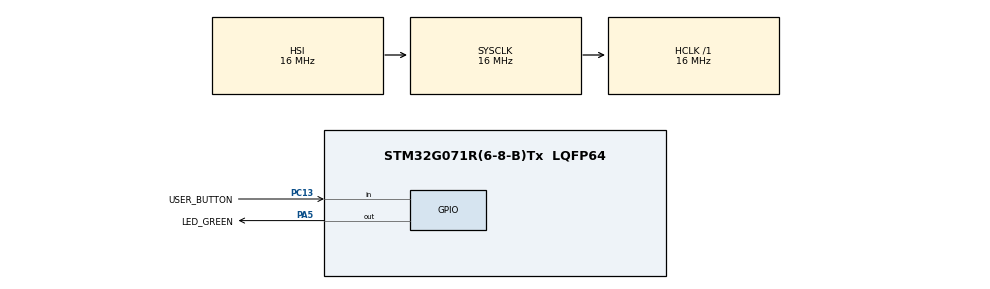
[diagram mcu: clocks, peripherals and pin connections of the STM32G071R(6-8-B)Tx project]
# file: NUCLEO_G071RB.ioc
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Mcu.Family=STM32G0
Mcu.Name=STM32G071R(6-8-B)Tx
Mcu.Package=LQFP64
PA13.GPIO_Label=TMS
PA13.Mode=Serial_Wire
PA13.Signal=SYS_SWDIO
PA14-BOOT0.GPIO_Label=TCK
PA14-BOOT0.Mode=Serial_Wire
PA14-BOOT0.Signal=SYS_SWCLK
PA5.GPIO_Label=LED_GREEN
PA5.GPIO_Speed=GPIO_SPEED_FREQ_HIGH
PA5.Signal=GPIO_Output
PC13.GPIO_Label=USER_BUTTON
PC13.GPIO_PuPd=GPIO_NOPULL
PC13.Signal=GPIO_Input
PC14-OSC32_IN\ (PC14).Mode=LSE-External-Oscillator
PC14-OSC32_IN\ (PC14).Signal=RCC_OSC32_IN
PC15-OSC32_OUT\ (PC15).Mode=LSE-External-Oscillator
PC15-OSC32_OUT\ (PC15).Signal=RCC_OSC32_OUT
PF0-OSC_IN\ (PF0).GPIO_Label=MCO
PF0-OSC_IN\ (PF0).Mode=HSE-External-Clock-Source
PF0-OSC_IN\ (PF0).Signal=RCC_OSC_IN
ProjectManager.HeapSize=0x200
ProjectManager.StackSize=0x400
ProjectManager.TargetToolchain=CMake
RCC.AHBFreq_Value=16000000
RCC.CortexFreq_Value=16000000
RCC.EXTERNAL_CLOCK_VALUE=12288000
RCC.HCLKFreq_Value=16000000
RCC.HSE_VALUE=8000000
RCC.HSI_VALUE=16000000
RCC.SYSCLKFreq_VALUE=16000000
RCC.VCOOutputFreq_Value=128000000
board=NUCLEO-G071RB

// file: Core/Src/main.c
/* USER CODE BEGIN Header */
/**
  ******************************************************************************
  * @file           : main.c
  * @brief          : Main program body
  ******************************************************************************
  * @attention
  *
  * Copyright (c) 2025 STMicroelectronics.
  * All rights reserved.
  *
  * This software is licensed under terms that can be found in the LICENSE file
  * in the root directory of this software component.
  * If no LICENSE file comes with this software, it is provided AS-IS.
  *
  ******************************************************************************
  */
/* USER CODE END Header */
#include "main.h"

/* USER CODE BEGIN Includes */
#include "main_app.h"
/* USER CODE END Includes */

void SystemClock_Config(void);
static void MX_GPIO_Init(void);

int main(void)
{

  /* MCU Configuration--------------------------------------------------------*/

  /* Reset of all peripherals, Initializes the Flash interface and the Systick. */
  HAL_Init();

  /* USER CODE BEGIN Init */
  // TESTS
  /* USER CODE END Init */

  /* Configure the system clock */
  SystemClock_Config();

  /* Initialize all configured peripherals */
  MX_GPIO_Init();

  /* Infinite loop */
  /* USER CODE BEGIN WHILE */
  while (1)
  {
    main_app();
    // if(GPIO_PIN_RESET == HAL_GPIO_ReadPin(USER_BUTTON_GPIO_Port, USER_BUTTON_Pin))
    // {
    //   HAL_GPIO_TogglePin( LED_GREEN_GPIO_Port, LED_GREEN_Pin);
    //   HAL_Delay(500);
    // }
    /* USER CODE END WHILE */

  }
}

void SystemClock_Config(void)
{
  RCC_OscInitTypeDef RCC_OscInitStruct = {0};
  RCC_ClkInitTypeDef RCC_ClkInitStruct = {0};

  /** Configure the main internal regulator output voltage
  */
  HAL_PWREx_ControlVoltageScaling(PWR_REGULATOR_VOLTAGE_SCALE1);

  /** Initializes the RCC Oscillators according to the specified parameters
  * in the RCC_OscInitTypeDef structure.
  */
  RCC_OscInitStruct.OscillatorType = RCC_OSCILLATORTYPE_HSI;
  RCC_OscInitStruct.HSIState = RCC_HSI_ON;
  RCC_OscInitStruct.HSIDiv = RCC_HSI_DIV1;
  RCC_OscInitStruct.HSICalibrationValue = RCC_HSICALIBRATION_DEFAULT;
  RCC_OscInitStruct.PLL.PLLState = RCC_PLL_NONE;
  if (HAL_RCC_OscConfig(&RCC_OscInitStruct) != HAL_OK)
  {
    Error_Handler();
  }

  /** Initializes the CPU, AHB and APB buses clocks
  */
  RCC_ClkInitStruct.ClockType = RCC_CLOCKTYPE_HCLK|RCC_CLOCKTYPE_SYSCLK
                              |RCC_CLOCKTYPE_PCLK1;
  RCC_ClkInitStruct.SYSCLKSource = RCC_SYSCLKSOURCE_HSI;
  RCC_ClkInitStruct.AHBCLKDivider = RCC_SYSCLK_DIV1;
  RCC_ClkInitStruct.APB1CLKDivider = RCC_HCLK_DIV1;

  if (HAL_RCC_ClockConfig(&RCC_ClkInitStruct, FLASH_LATENCY_0) != HAL_OK)
  {
    Error_Handler();
  }
}

static void MX_GPIO_Init(void)
{
  GPIO_InitTypeDef GPIO_InitStruct = {0};

  /* GPIO Ports Clock Enable */
  __HAL_RCC_GPIOC_CLK_ENABLE();
  __HAL_RCC_GPIOF_CLK_ENABLE();
  __HAL_RCC_GPIOA_CLK_ENABLE();

  /*Configure GPIO pin Output Level */
  HAL_GPIO_WritePin(LED_GREEN_GPIO_Port, LED_GREEN_Pin, GPIO_PIN_RESET);

  /*Configure GPIO pin : USER_BUTTON_Pin */
  GPIO_InitStruct.Pin = USER_BUTTON_Pin;
  GPIO_InitStruct.Mode = GPIO_MODE_INPUT;
  GPIO_InitStruct.Pull = GPIO_NOPULL;
  HAL_GPIO_Init(USER_BUTTON_GPIO_Port, &GPIO_InitStruct);

  /*Configure GPIO pin : LED_GREEN_Pin */
  GPIO_InitStruct.Pin = LED_GREEN_Pin;
  GPIO_InitStruct.Mode = GPIO_MODE_OUTPUT_PP;
  GPIO_InitStruct.Pull = GPIO_NOPULL;
  GPIO_InitStruct.Speed = GPIO_SPEED_FREQ_HIGH;
  HAL_GPIO_Init(LED_GREEN_GPIO_Port, &GPIO_InitStruct);

}

void Error_Handler(void)
{
  __disable_irq();
  while (1)
  {
  }
}
